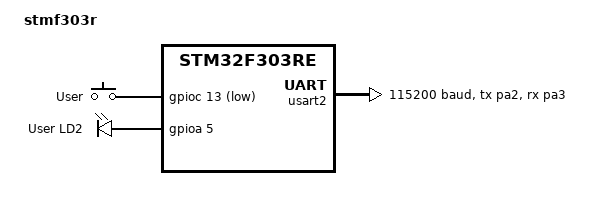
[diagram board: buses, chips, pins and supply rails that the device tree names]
/dts-v1/;
#include <st/f3/stm32f303Xe.dtsi>
#include "stmf303r-pinctrl.dtsi"
#include "arduino_r3_connector.dtsi"
#include "st_morpho_connector.dtsi"
#include <zephyr/dt-bindings/input/input-event-codes.h>


/ {
	model = "stmf303r";
	compatible = "st,stm32f303re-nucleo";

    aliases {
		led0 = &green_led_2;
		sw0 = &user_button;
	};


    chosen {
		zephyr,console = &usart2;
		zephyr,shell-uart = &usart2;
		zephyr,sram = &sram0;
		zephyr,flash = &flash0;
		zephyr,canbus = &can1;
	};

    gpio_keys {
		compatible = "gpio-keys";
		user_button: button {
			label = "User";
			gpios = <&gpioc 13 GPIO_ACTIVE_LOW>;
			zephyr,code = <INPUT_KEY_0>;
		};
	};

    leds: leds {
		compatible = "gpio-leds";
		green_led_2: led_2 {
			gpios = <&gpioa 5 GPIO_ACTIVE_HIGH>;
			label = "User LD2";
		};
	};

    

};

    &rcc {
	clocks = <&pll>;
	clock-frequency = <DT_FREQ_M(72)>;
	ahb-prescaler = <1>;
	apb1-prescaler = <2>;
	apb2-prescaler = <1>;
	adc12-prescaler = <0>;
	adc34-prescaler = <0>;
};

    &usart2 {
	pinctrl-0 = <&usart2_tx_pa2 &usart2_rx_pa3>;
	pinctrl-names = "default";
	current-speed = <115200>;
	status = "okay";
};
